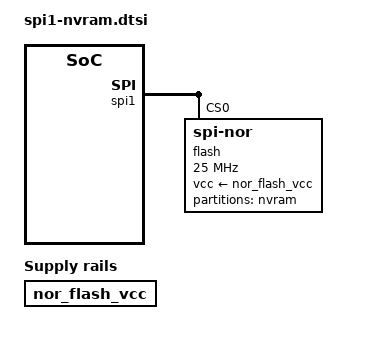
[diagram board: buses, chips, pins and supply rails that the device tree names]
// SPDX-License-Identifier: GPL-2.0+ OR MIT
//
// Devicetree include for common spi-nor nvram flash.
//
// Apple uses a consistent configuration for the nvram on all known M1* and
// M2* devices.
//
// Copyright The Asahi Linux Contributors

/ {
	aliases {
		nvram = &nvram;
	};

	/*
	 * The boot NOR runs from a PMU rail that is on whenever the SoC is
	 * and that no OS switches. The ADT gives the flash no supply.
	 */
	nor_flash_vcc: regulator-nor-flash-vcc {
		compatible = "regulator-fixed";
		regulator-name = "nor-flash-vcc";
		regulator-always-on;
	};
};

&spi1 {
	status = "okay";

	flash@0 {
		compatible = "jedec,spi-nor";
		reg = <0x0>;
		spi-max-frequency = <25000000>;
		vcc-supply = <&nor_flash_vcc>;

		partitions {
			compatible = "fixed-partitions";
			#address-cells = <1>;
			#size-cells = <1>;

			nvram: partition@700000 {
				label = "nvram";
				/* To be filled by the loader */
				reg = <0x0 0x0>;
				status = "disabled";
			};
		};
	};
};
